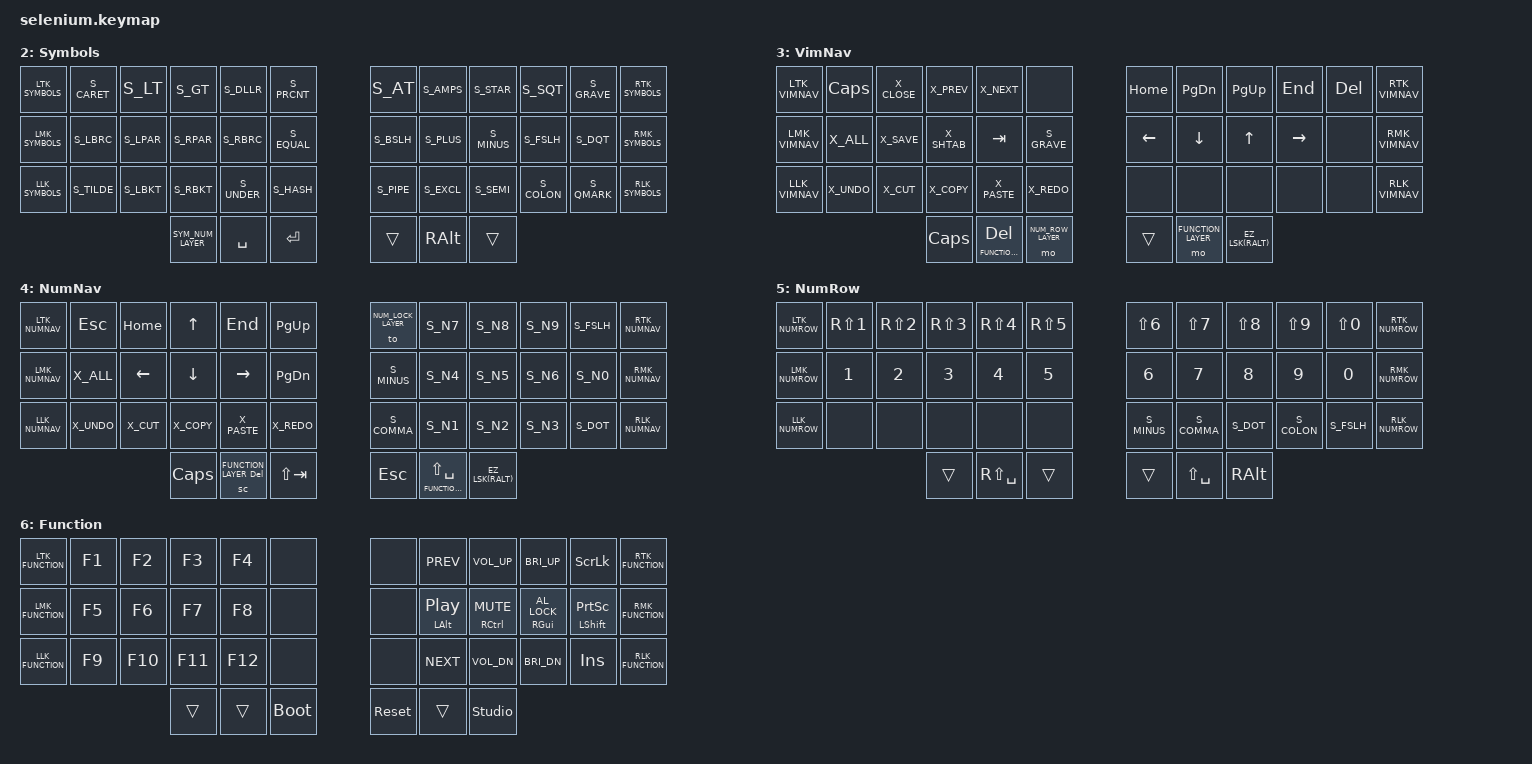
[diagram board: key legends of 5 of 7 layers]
// Selenium keymap for the Quacken: https://github.com/OneDeadKey/selenium

#pragma once

/******************************************************************************
 * Layout-specific actions and symbols.
******************************************************************************/

// Uncomment one of the folowing lines if using a non-QWERTY layout:

// #define KB_LAYOUT_QWERTY_LAFAYETTE
// #define KB_LAYOUT_AZERTY
// #define KB_LAYOUT_ERGOL

// Uncomment the folowing line if using a Mac:

// #define MACOS


/******************************************************************************
 * Hold-Taps
******************************************************************************/

// Uncomment one of the folowing lines to pick your preferred hold-tap config:

// #define HT_NONE
// #define HT_THUMB_TAPS
// #define HT_HOME_ROW_MODS  // (default behavior)
// #define HT_TWO_THUMB_KEYS

// Timing is key! Keep the default value if unsure.
// This defines how long (in ms) a hold-tap key with the "tap-preferred" flavor
// must be held to be considered as a modifier or layer shift. These hold-taps
// are the ones that may produce text, including the space-bar and home-row-mods.
// Keep this value high if you struggle wih home-row-mods.

// #define TAPPING_TERM 300

// This defines how quickly (in ms) you need to press and release a hold-tap
// with the "hold-preferred" flavor for it to be considered a tap. These
// hold-taps include the ones that don’t produce text when tapped.
// Keep this value low if you press Enter or Escape by mistake too often.

// #define SHORT_TAPPING_TERM 150

// When tapping then holding the same tap-hold, if the delay between the two
// key presses is lower than `QUICK_TAP`, the tap-hold will hold the tap action
// instead of the hold action. Again, keep the default value if unsure.

// #define QUICK_TAP 200

// For more information on how hold-taps operate, feel free to read ZMK’s docs:
// https://zmk.dev/docs/keymaps/behaviors/hold-tap

/******************************************************************************
 * Other Options
*****************************************************************************/

// Uncomment the following line to plit the num-nav layer in two:
//  - one layer for vim-style navigation (right) and GUI shortcuts (left)
//  - one layer for a full number row + easy access to Shift+Number
//  + Escape under the left thumb (direct access)
// Highly recommended for Vim users, obviously. :-)

// #define VIM_NAVIGATION

// Uncomment the following line to enable shift as a pinky HRM.
// Useful for combined shortcuts, but NOT MEANT to type text!

// #define HRM_SHIFT

// Uncomment the following line to swap Space and Backspace.
// Beware: this increases the typing load of the left thumb.

// #define LEFT_HAND_SPACE


/******************************************************************************
 * Keymap
******************************************************************************/

#include "aliases.h"      // defines symbols and actions
#include "hold_taps.dtsi" // defines thumb keys and homerow mods

// Left Top Keys
#ifndef LTK_BASE
#define LTK_BASE
#endif
// Left Middle Keys
#ifndef LMK_BASE
#define LMK_BASE
#endif
// Left Lower Keys
#ifndef LLK_BASE
#define LLK_BASE
#endif


// Middle Top Keys
#ifndef MTK_BASE
#define MTK_BASE
#endif
// Middle Middle Keys
#ifndef MMK_BASE
#define MMK_BASE
#endif
// Middle Lower Keys
#ifndef MLK_BASE
#define MLK_BASE
#endif


// Right Top Keys
#ifndef RTK_BASE
#define RTK_BASE
#endif
// Right Middle Keys
#ifndef RMK_BASE
#define RMK_BASE
#endif
// Right Lower Keys
#ifndef RLK_BASE
#define RLK_BASE
#endif


// NumLock
// Left Top Keys
#ifndef LTK_NUMLOCK
#define LTK_NUMLOCK
#endif
// Left Middle Keys
#ifndef LMK_NUMLOCK
#define LMK_NUMLOCK
#endif
// Left Lower Keys
#ifndef LLK_NUMLOCK
#define LLK_NUMLOCK
#endif


// Middle Top Keys
#ifndef MTK_NUMLOCK
#define MTK_NUMLOCK
#endif
// Middle Middle Keys
#ifndef MMK_NUMLOCK
#define MMK_NUMLOCK
#endif
// Middle Lower Keys
#ifndef MLK_NUMLOCK
#define MLK_NUMLOCK
#endif


// Right Top Keys
#ifndef RTK_NUMLOCK
#define RTK_NUMLOCK
#endif
// Right Middle Keys
#ifndef RMK_NUMLOCK
#define RMK_NUMLOCK
#endif
// Right Lower Keys
#ifndef RLK_NUMLOCK
#define RLK_NUMLOCK
#endif


// Symbols
// Left Top Keys
#ifndef LTK_SYMBOLS
#define LTK_SYMBOLS
#endif
// Left Middle Keys
#ifndef LMK_SYMBOLS
#define LMK_SYMBOLS
#endif
// Left Lower Keys
#ifndef LLK_SYMBOLS
#define LLK_SYMBOLS
#endif


// Middle Top Keys
#ifndef MTK_SYMBOLS
#define MTK_SYMBOLS
#endif
// Middle Middle Keys
#ifndef MMK_SYMBOLS
#define MMK_SYMBOLS
#endif
// Middle Lower Keys
#ifndef MLK_SYMBOLS
#define MLK_SYMBOLS
#endif


// Right Top Keys
#ifndef RTK_SYMBOLS
#define RTK_SYMBOLS
#endif
// Right Middle Keys
#ifndef RMK_SYMBOLS
#define RMK_SYMBOLS
#endif
// Right Lower Keys
#ifndef RLK_SYMBOLS
#define RLK_SYMBOLS
#endif


// VimNav
// Left Top Keys
#ifndef LTK_VIMNAV
#define LTK_VIMNAV
#endif
// Left Middle Keys
#ifndef LMK_VIMNAV
#define LMK_VIMNAV
#endif
// Left Lower Keys
#ifndef LLK_VIMNAV
#define LLK_VIMNAV
#endif


// Middle Top Keys
#ifndef MTK_VIMNAV
#define MTK_VIMNAV
#endif
// Middle Middle Keys
#ifndef MMK_VIMNAV
#define MMK_VIMNAV
#endif
// Middle Lower Keys
#ifndef MLK_VIMNAV
#define MLK_VIMNAV
#endif


// Right Top Keys
#ifndef RTK_VIMNAV
#define RTK_VIMNAV
#endif
// Right Middle Keys
#ifndef RMK_VIMNAV
#define RMK_VIMNAV
#endif
// Right Lower Keys
#ifndef RLK_VIMNAV
#define RLK_VIMNAV
#endif


// NumNav
// Left Top Keys
#ifndef LTK_NUMNAV
#define LTK_NUMNAV
#endif
// Left Middle Keys
#ifndef LMK_NUMNAV
#define LMK_NUMNAV
#endif
// Left Lower Keys
#ifndef LLK_NUMNAV
#define LLK_NUMNAV
#endif


// Middle Top Keys
#ifndef MTK_NUMNAV
#define MTK_NUMNAV
#endif
// Middle Middle Keys
#ifndef MMK_NUMNAV
#define MMK_NUMNAV
#endif
// Middle Lower Keys
#ifndef MLK_NUMNAV
#define MLK_NUMNAV
#endif


// Right Top Keys
#ifndef RTK_NUMNAV
#define RTK_NUMNAV
#endif
// Right Middle Keys
#ifndef RMK_NUMNAV
#define RMK_NUMNAV
#endif
// Right Lower Keys
#ifndef RLK_NUMNAV
#define RLK_NUMNAV
#endif


// NumRow
// Left Top Keys
#ifndef LTK_NUMROW
#define LTK_NUMROW
#endif
// Left Middle Keys
#ifndef LMK_NUMROW
#define LMK_NUMROW
#endif
// Left Lower Keys
#ifndef LLK_NUMROW
#define LLK_NUMROW
#endif


// Middle Top Keys
#ifndef MTK_NUMROW
#define MTK_NUMROW
#endif
// Middle Middle Keys
#ifndef MMK_NUMROW
#define MMK_NUMROW
#endif
// Middle Lower Keys
#ifndef MLK_NUMROW
#define MLK_NUMROW
#endif


// Right Top Keys
#ifndef RTK_NUMROW
#define RTK_NUMROW
#endif
// Right Middle Keys
#ifndef RMK_NUMROW
#define RMK_NUMROW
#endif
// Right Lower Keys
#ifndef RLK_NUMROW
#define RLK_NUMROW
#endif


// VimNav
// Left Top Keys
#ifndef LTK_FUNCTION
#define LTK_FUNCTION
#endif
// Left Middle Keys
#ifndef LMK_FUNCTION
#define LMK_FUNCTION
#endif
// Left Lower Keys
#ifndef LLK_FUNCTION
#define LLK_FUNCTION
#endif


// Middle Top Keys
#ifndef MTK_FUNCTION
#define MTK_FUNCTION
#endif
// Middle Middle Keys
#ifndef MMK_FUNCTION
#define MMK_FUNCTION
#endif
// Middle Lower Keys
#ifndef MLK_FUNCTION
#define MLK_FUNCTION
#endif


// Right Top Keys
#ifndef RTK_FUNCTION
#define RTK_FUNCTION
#endif
// Right Middle Keys
#ifndef RMK_FUNCTION
#define RMK_FUNCTION
#endif
// Right Lower Keys
#ifndef RLK_FUNCTION
#define RLK_FUNCTION
#endif


// Azerty Base
// Left Top Keys
#ifndef LTK_AZERTY
#define LTK_AZERTY
#endif
// Left Middle Keys
#ifndef LMK_AZERTY
#define LMK_AZERTY
#endif
// Left Lower Keys
#ifndef LLK_AZERTY
#define LLK_AZERTY
#endif


// Middle Top Keys
#ifndef MTK_AZERTY
#define MTK_AZERTY
#endif
// Middle Middle Keys
#ifndef MMK_AZERTY
#define MMK_AZERTY
#endif
// Middle Lower Keys
#ifndef MLK_AZERTY
#define MLK_AZERTY
#endif


// Right Top Keys
#ifndef RTK_AZERTY
#define RTK_AZERTY
#endif
// Right Middle Keys
#ifndef RMK_AZERTY
#define RMK_AZERTY
#endif
// Right Lower Keys
#ifndef RLK_AZERTY
#define RLK_AZERTY
#endif


// DeadKey
// Left Top Keys
#ifndef LTK_DEADKEY
#define LTK_DEADKEY
#endif
// Left Middle Keys
#ifndef LMK_DEADKEY
#define LMK_DEADKEY
#endif
// Left Lower Keys
#ifndef LLK_DEADKEY
#define LLK_DEADKEY
#endif


// Middle Top Keys
#ifndef MTK_DEADKEY
#define MTK_DEADKEY
#endif
// Middle Middle Keys
#ifndef MMK_DEADKEY
#define MMK_DEADKEY
#endif
// Middle Lower Keys
#ifndef MLK_DEADKEY
#define MLK_DEADKEY
#endif


// Right Top Keys
#ifndef RTK_DEADKEY
#define RTK_DEADKEY
#endif
// Right Middle Keys
#ifndef RMK_DEADKEY
#define RMK_DEADKEY
#endif
// Right Lower Keys
#ifndef RLK_DEADKEY
#define RLK_DEADKEY
#endif


// HummingBird Base
// Left Top Keys
#ifndef LTK_HB_BASE
#define LTK_HB_BASE
#endif
// Left Middle Keys
#ifndef LMK_HB_BASE
#define LMK_HB_BASE
#endif
// Left Lower Keys
#ifndef LLK_HB_BASE
#define LLK_HB_BASE
#endif


// Middle Top Keys
#ifndef MTK_HB_BASE
#define MTK_HB_BASE
#endif
// Middle Middle Keys
#ifndef MMK_HB_BASE
#define MMK_HB_BASE
#endif
// Middle Lower Keys
#ifndef MLK_HB_BASE
#define MLK_HB_BASE
#endif


// Right Top Keys
#ifndef RTK_HB_BASE
#define RTK_HB_BASE
#endif
// Right Middle Keys
#ifndef RMK_HB_BASE
#define RMK_HB_BASE
#endif
// Right Lower Keys
#ifndef RLK_HB_BASE
#define RLK_HB_BASE
#endif


// HummingBird Symbols
// Left Top Keys
#ifndef LTK_HB_SYMBOLS
#define LTK_HB_SYMBOLS
#endif
// Left Middle Keys
#ifndef LMK_HB_SYMBOLS
#define LMK_HB_SYMBOLS
#endif
// Left Lower Keys
#ifndef LLK_HB_SYMBOLS
#define LLK_HB_SYMBOLS
#endif


// Middle Top Keys
#ifndef MTK_HB_SYMBOLS
#define MTK_HB_SYMBOLS
#endif
// Middle Middle Keys
#ifndef MMK_HB_SYMBOLS
#define MMK_HB_SYMBOLS
#endif
// Middle Lower Keys
#ifndef MLK_HB_SYMBOLS
#define MLK_HB_SYMBOLS
#endif


// Right Top Keys
#ifndef RTK_HB_SYMBOLS
#define RTK_HB_SYMBOLS
#endif
// Right Middle Keys
#ifndef RMK_HB_SYMBOLS
#define RMK_HB_SYMBOLS
#endif
// Right Lower Keys
#ifndef RLK_HB_SYMBOLS
#define RLK_HB_SYMBOLS
#endif


// DeadKey
// Left Top Keys
#ifndef LTK_HB_ODK
#define LTK_HB_ODK
#endif
// Left Middle Keys
#ifndef LMK_HB_ODK
#define LMK_HB_ODK
#endif
// Left Lower Keys
#ifndef LLK_HB_ODK
#define LLK_HB_ODK
#endif


// Middle Top Keys
#ifndef MTK_HB_ODK
#define MTK_HB_ODK
#endif
// Middle Middle Keys
#ifndef MMK_HB_ODK
#define MMK_HB_ODK
#endif
// Middle Lower Keys
#ifndef MLK_HB_ODK
#define MLK_HB_ODK
#endif


// Right Top Keys
#ifndef RTK_HB_ODK
#define RTK_HB_ODK
#endif
// Right Middle Keys
#ifndef RMK_HB_ODK
#define RMK_HB_ODK
#endif
// Right Lower Keys
#ifndef RLK_HB_ODK
#define RLK_HB_ODK
#endif


// Shifted DeadKey
// Left Top Keys
#ifndef LTK_HB_SODK
#define LTK_HB_SODK
#endif
// Left Middle Keys
#ifndef LMK_HB_SODK
#define LMK_HB_SODK
#endif
// Left Lower Keys
#ifndef LLK_HB_SODK
#define LLK_HB_SODK
#endif


// Middle Top Keys
#ifndef MTK_HB_SODK
#define MTK_HB_SODK
#endif
// Middle Middle Keys
#ifndef MMK_HB_SODK
#define MMK_HB_SODK
#endif
// Middle Lower Keys
#ifndef MLK_HB_SODK
#define MLK_HB_SODK
#endif


// Right Top Keys
#ifndef RTK_HB_SODK
#define RTK_HB_SODK
#endif
// Right Middle Keys
#ifndef RMK_HB_SODK
#define RMK_HB_SODK
#endif
// Right Lower Keys
#ifndef RLK_HB_SODK
#define RLK_HB_SODK
#endif


// Extra Symbols
// Left Top Keys
#ifndef LTK_HB_EXTRA_SYMS
#define LTK_HB_EXTRA_SYMS
#endif
// Left Middle Keys
#ifndef LMK_HB_EXTRA_SYMS
#define LMK_HB_EXTRA_SYMS
#endif
// Left Lower Keys
#ifndef LLK_HB_EXTRA_SYMS
#define LLK_HB_EXTRA_SYMS
#endif


// Middle Top Keys
#ifndef MTK_HB_EXTRA_SYMS
#define MTK_HB_EXTRA_SYMS
#endif
// Middle Middle Keys
#ifndef MMK_HB_EXTRA_SYMS
#define MMK_HB_EXTRA_SYMS
#endif
// Middle Lower Keys
#ifndef MLK_HB_EXTRA_SYMS
#define MLK_HB_EXTRA_SYMS
#endif


// Right Top Keys
#ifndef RTK_HB_EXTRA_SYMS
#define RTK_HB_EXTRA_SYMS
#endif
// Right Middle Keys
#ifndef RMK_HB_EXTRA_SYMS
#define RMK_HB_EXTRA_SYMS
#endif
// Right Lower Keys
#ifndef RLK_HB_EXTRA_SYMS
#define RLK_HB_EXTRA_SYMS
#endif


/ {
  keymap {
    compatible = "zmk,keymap";

    // 0. Base layer -- keep the QWERTY key codes to use your OS keyboard layout
    //               -- the Space Cadet layer-tap on the right can be replaced by an AltGr/Enter mod-tap
    //               -- adjust the homerow mods with the #define statements above
    base_layer: base_layer {
      display-name = "Base";
      bindings = <
        LTK_BASE   &kp Q  &kp W  &kp E  &kp R  &kp T   MTK_BASE     &kp Y  &kp U  &kp I     &kp O   &kp P      RTK_BASE
        LMK_BASE   HRM_A  HRM_S  HRM_D  HRM_F  &kp G   MMK_BASE     &kp H  HRM_J  HRM_K     HRM_L   HRM_SEMI   RMK_BASE
        LLK_BASE   &kp Z  &kp X  &kp C  &kp V  &kp B   MLK_BASE     &kp N  &kp M  &kp COMMA &kp DOT &kp FSLH   LLK_BASE
                LTHUMB_TUCK  LTHUMB_HOME  LTHUMB_REACH          RTHUMB_REACH  RTHUMB_HOME  RTHUMB_TUCK
      >;
    };

    // 1. NumLock layer -- NavNum layer that stays on until deactivated without holding key
    num_lock_layer: num_lock_layer {
      display-name = "NumLock";
      bindings = <
        LTK_NUMLOCK  &kp ESC  &kp HOME &kp UP   &kp END   &kp PG_UP    &to BASE_LAYER S_N7  S_N8  S_N9  S_FSLH  RTK_NUMLOCK
        LMK_NUMLOCK  S_EQUAL  &kp LEFT &kp DOWN &kp RIGHT &kp PG_DN    S_MINUS        S_N4  S_N5  S_N6  S_N0    RMK_NUMLOCK
        LLK_NUMLOCK  S_MONEY  S_COLON  S_STAR   S_PLUS    S_PRCNT      S_COMMA        S_N1  S_N2  S_N3  S_DOT   RLK_NUMLOCK
                 &trans  &sc NUM_NAV_LAYER BACKSPACE  &kp (TAB)  &trans  &lt NUM_NAV_LAYER LS(SPACE)  &EZ_SL(SYMBOLS_LAYER)
      >;
    };

    // 2. Symbols layer -- with Ergol, basically just an AltGr layer with custom thumb keys
    //                  -- can be redefined for non-AltGr layouts such as QWERTY-ANSI
    symbols_layer: symbols_layer {
      display-name = "Symbols";
      bindings = <
        LTK_SYMBOLS  S_CARET S_LT    S_GT    S_DLLR  S_PRCNT       S_AT    S_AMPS  S_STAR  S_SQT   S_GRAVE  RTK_SYMBOLS
        LMK_SYMBOLS  S_LBRC  S_LPAR  S_RPAR  S_RBRC  S_EQUAL       S_BSLH  S_PLUS  S_MINUS S_FSLH  S_DQT    RMK_SYMBOLS
        LLK_SYMBOLS  S_TILDE S_LBKT  S_RBKT  S_UNDER S_HASH        S_PIPE  S_EXCL  S_SEMI  S_COLON S_QMARK  RLK_SYMBOLS
                    SYM_NUM_LAYER  &kp SPACE  &kp ENTER     &trans  &kp RALT  &trans
      >;
    };

    // 3. VimNav layer -- HJKL arrow cluster on the right hand
    //                 -- best used along with the NumRow layer
    //                 -- keyboard shortcuts on the left hand are adjusted to the OS layout (Ergol here)
    vim_nav_layer: vim_nav_layer {
      display-name = "VimNav";
      bindings = <
        LTK_VIMNAV  &kp CAPS X_CLOSE  X_PREV   X_NEXT    &none        &kp HOME &kp PG_DN &kp PG_UP &kp END   &kp DEL RTK_VIMNAV
        LMK_VIMNAV  X_ALL    X_SAVE   X_SHTAB  &kp TAB   S_GRAVE      &kp LEFT &kp DOWN  &kp UP    &kp RIGHT &none   RMK_VIMNAV
        LLK_VIMNAV  X_UNDO   X_CUT    X_COPY   X_PASTE   X_REDO       &none    &none     &none     &none     &none   RLK_VIMNAV
        &kp CAPSLOCK  &lt FUNCTION_LAYER DEL  &mo NUM_ROW_LAYER   &trans   &mo FUNCTION_LAYER  &EZ_LSK(RALT)
      >;
    };

    // 4. NumNav layer -- inverted T arrow cluster on the left hand, numpad on the right hand
    //                 -- can be the only extra layer you need if you're not too picky with number+symbols n-grams
    //                 -- keyboard shortcuts on the left hand are adjusted to the OS layout (Ergol here)
    num_nav_layer: num_nav_layer {
      display-name = "NumNav";
      bindings = <
        LTK_NUMNAV  &kp ESC  &kp HOME &kp UP   &kp END   &kp PG_UP    &to NUM_LOCK_LAYER S_N7  S_N8  S_N9  S_FSLH  RTK_NUMNAV
        LMK_NUMNAV  X_ALL    &kp LEFT &kp DOWN &kp RIGHT &kp PG_DN    S_MINUS            S_N4  S_N5  S_N6  S_N0    RMK_NUMNAV
        LLK_NUMNAV  X_UNDO   X_CUT    X_COPY   X_PASTE   X_REDO       S_COMMA            S_N1  S_N2  S_N3  S_DOT   RLK_NUMNAV
               &kp CAPSLOCK  &sc FUNCTION_LAYER DEL  &kp LS(TAB)  &kp ESCAPE  &lt FUNCTION_LAYER LS(SPACE)  &EZ_LSK(RALT)
      >;
    };

    // 5. NumRow layer -- bring the numbers to the homerow, keep shift+numbers for shortcuts and symbols
    //                 -- space becomes shift+space, which is a no-break space with some OS layouts (e.g. Ergol)
    //                 -- best used along with the VimNav layer
    num_row_layer: num_row_layer {
      display-name = "NumRow";
      bindings = <
        LTK_NUMROW  &kp RS(N1) &kp RS(N2) &kp RS(N3) &kp RS(N4) &kp RS(N5)       &kp LS(N6) &kp LS(N7) &kp LS(N8) &kp LS(N9) &kp LS(N0) RTK_NUMROW
        LMK_NUMROW  &kp N1     &kp N2     &kp N3     &kp N4     &kp N5           &kp N6     &kp N7     &kp N8     &kp N9     &kp N0     RMK_NUMROW
        LLK_NUMROW  &none      &none      &none      &none      &none            S_MINUS    S_COMMA    S_DOT      S_COLON    S_FSLH     RLK_NUMROW
                                      &trans  &kp RS(SPACE) &trans           &trans  &kp LS(SPACE) &kp RALT
      >;
    };

    // 6. Function layer -- F1..12 pad on the left hand, HRM on the right hand (with an additional Shift key)
    //                   -- reset and bootloader reset on difficult thumb keys
    //                   -- could be completed with other rare keys
    function_layer: function_layer {
      display-name = "Function";
      bindings = <
        LTK_FUNCTION  &kp F1  &kp F2  &kp F3  &kp F4  &none         &none &kp C_PREV     &kp C_VOL_UP     &kp C_BRI_UP        &kp SLCK           RTK_FUNCTION
        LMK_FUNCTION  &kp F5  &kp F6  &kp F7  &kp F8  &none         &none &hrm LALT C_PP &hrm RCTL C_MUTE &hrm RGUI C_AL_LOCK &hrm LSHIFT PSCRN  RMK_FUNCTION
        LLK_FUNCTION  &kp F9  &kp F10 &kp F11 &kp F12 &none         &none &kp C_NEXT     &kp C_VOL_DN     &kp C_BRI_DN        &kp INS            RLK_FUNCTION
                                &trans  &trans  &bootloader   &sys_reset  &trans  &studio_unlock
      >;
    };
  };
};

// Some layouts require extra layers to fit on the Quacken.
#ifdef KB_LAYOUT_AZERTY
  #include "extra_layers/azerty.dtsi"
#elif defined KB_LAYOUT_ERGOL && defined HUMMINGBIRD
  #include "extra_layers/ergol_hummingbird.dtsi"
#endif
